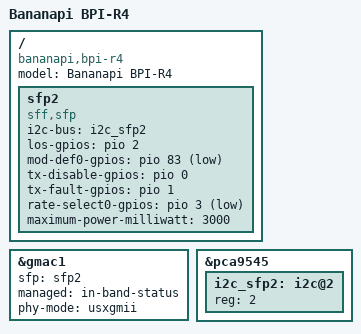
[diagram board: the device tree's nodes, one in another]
// SPDX-License-Identifier: (GPL-2.0 OR MIT)
/*
 * Copyright (C) 2022 MediaTek Inc.
 * Author: Sam.Shih <sam.shih@mediatek.com>
 */

#include "mt7988a-bananapi-bpi-r4.dtsi"

/ {
	model = "Bananapi BPI-R4";
	compatible = "bananapi,bpi-r4",
		     "mediatek,mt7988a";

	/* SFP2 cage (LAN) */
	sfp2: sfp2 {
		compatible = "sff,sfp";
		i2c-bus = <&i2c_sfp2>;
		los-gpios = <&pio 2 GPIO_ACTIVE_HIGH>;
		mod-def0-gpios = <&pio 83 GPIO_ACTIVE_LOW>;
		tx-disable-gpios = <&pio 0 GPIO_ACTIVE_HIGH>;
		tx-fault-gpios = <&pio 1 GPIO_ACTIVE_HIGH>;
		rate-select0-gpios = <&pio 3 GPIO_ACTIVE_LOW>;
		maximum-power-milliwatt = <3000>;
	};
};

&gmac1 {
	sfp = <&sfp2>;
	managed = "in-band-status";
	phy-mode = "usxgmii";
	status = "okay";
};

&pca9545 {
	i2c_sfp2: i2c@2 {
		#address-cells = <1>;
		#size-cells = <0>;
		reg = <2>;
	};
};
